# STM32F765BGT6 register map
File version: 1.0
Registers are 32-bit, access not given, reset 0x0 unless marked. A register's access mark holds for its fields unless they carry their own. Offsets are from the block's base; [hi:lo] are bit positions; {n}, {i} and the like mark numbered series.

## MDIOS
Base 0x40017800
0x00 CR
  [12:8] PORT_ADDRESS, [31:4] s, [3] EEI, [2] RDIE, [1] WRIE, [0] EN
0x04 WRFR
  [31:0] WRF
0x08 CWRFR
  [31:0] CWRF
0x0C RDFR
  [31:0] RDF
0x10 CRDFR
  [31:0] CRDF
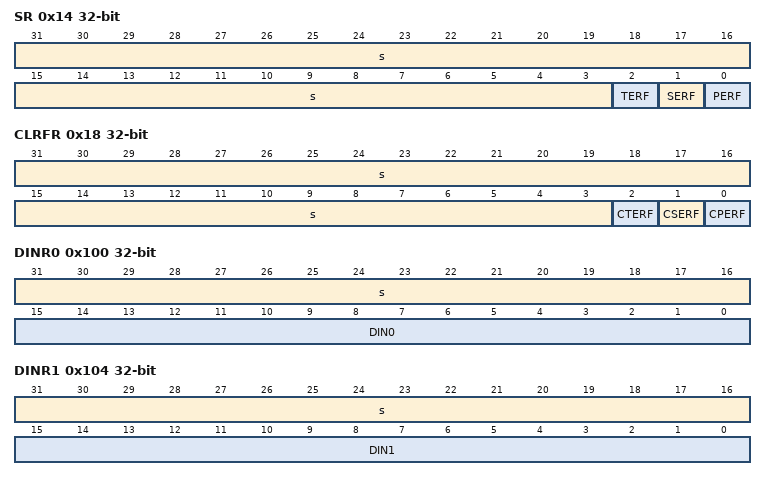
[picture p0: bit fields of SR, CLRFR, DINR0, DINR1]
0x14 SR
  [31:3] s, [2] TERF, [1] SERF, [0] PERF
0x18 CLRFR
  [31:3] s, [2] CTERF, [1] CSERF, [0] CPERF
0x100 DINR0
  [31:16] s, [15:0] DIN0
0x104 DINR1
  [31:16] s, [15:0] DIN1
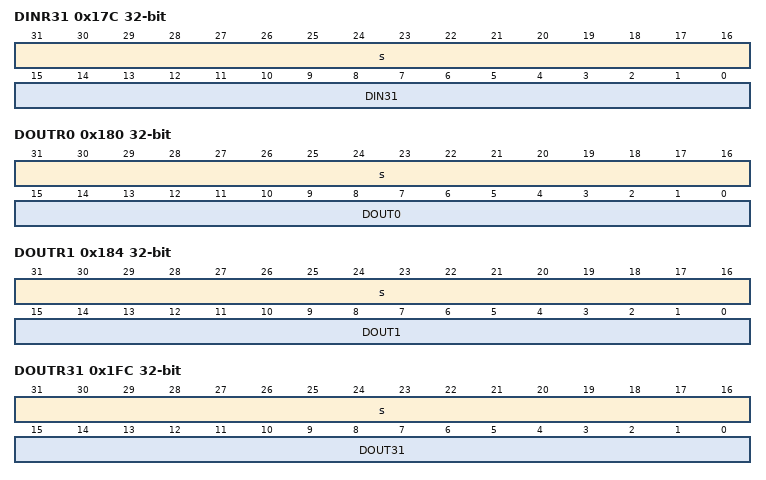
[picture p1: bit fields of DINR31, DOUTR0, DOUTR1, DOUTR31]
0x17C DINR31
  [31:16] s, [15:0] DIN31
0x180 DOUTR0
  [31:16] s, [15:0] DOUT0
0x184 DOUTR1
  [31:16] s, [15:0] DOUT1
0x1FC DOUTR31
  [31:16] s, [15:0] DOUT31

## GPIOA
Base 0x40020000
Same registers: GPIOB 0x40020400
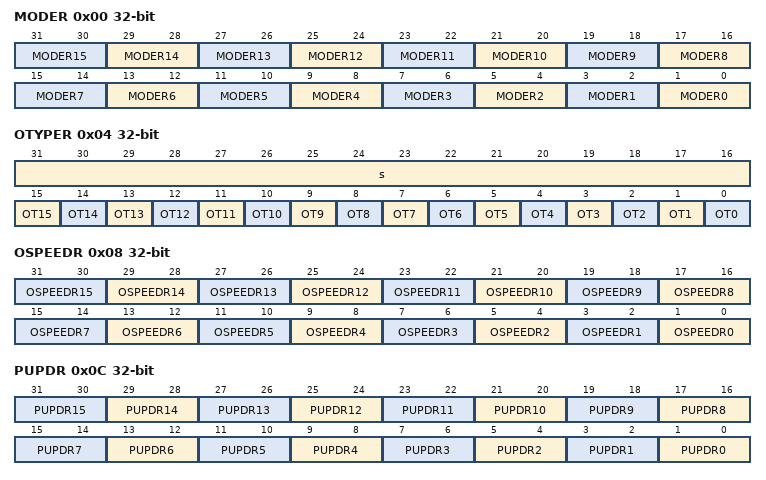
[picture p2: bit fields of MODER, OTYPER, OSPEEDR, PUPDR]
0x00 MODER
  [2n+1:2n] MODER{n} (n=0..15)
0x04 OTYPER
  [31:16] s, [n] OT{n} (n=0..15)
0x08 OSPEEDR
  [2n+1:2n] OSPEEDR{n} (n=0..15)
0x0C PUPDR
  [2n+1:2n] PUPDR{n} (n=0..15)
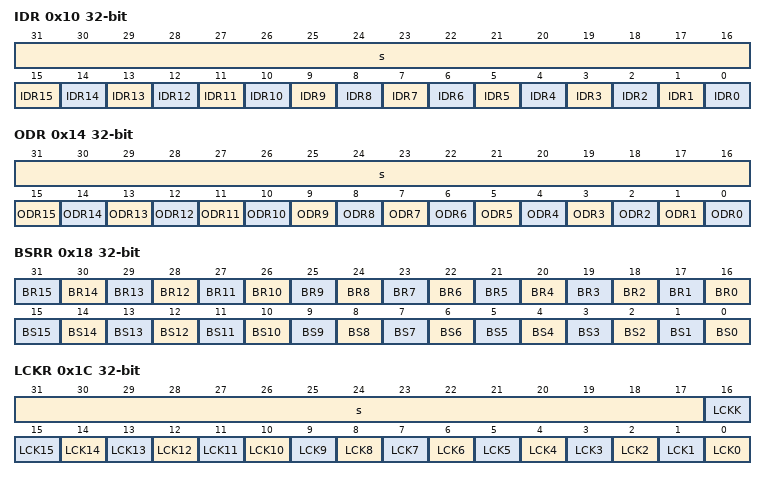
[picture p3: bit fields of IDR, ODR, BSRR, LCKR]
0x10 IDR
  [31:16] s, [n] IDR{n} (n=0..15)
0x14 ODR
  [31:16] s, [n] ODR{n} (n=0..15)
0x18 BSRR
  [n+16] BR{n} (n=0..15), [n] BS{n} (n=0..15)
0x1C LCKR
  [31:17] s, [16] LCKK, [n] LCK{n} (n=0..15)
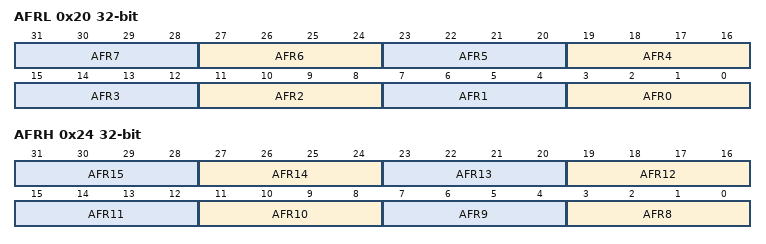
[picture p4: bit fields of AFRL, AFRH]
0x20 AFRL
  [4n+3:4n] AFR{n} (n=0..7)
0x24 AFRH
  [4n-29:4n-32] AFR{n} (n=8..15)

## GPIOC
Base 0x40020800
Registers as GPIOA, without PUPDR.

## GPIOD
Base 0x40020C00
Registers as GPIOA, without PUPDR.

## GPIOE
Base 0x40021000
Registers as GPIOA, without PUPDR.

## GPIOF
Base 0x40021400
Registers as GPIOA, without PUPDR.

## GPIOG
Base 0x40021800
Registers as GPIOA, without PUPDR.

## GPIOH
Base 0x40021C00
Registers as GPIOA, without PUPDR.

## GPIOI
Base 0x40022000
Registers as GPIOA, without PUPDR.

## GPIOJ
Base 0x40022400
Registers as GPIOA, without PUPDR.

## GPIOK
Base 0x40022800
Registers as GPIOA, without PUPDR.

## CRC
Base 0x40023000
0x00 DR
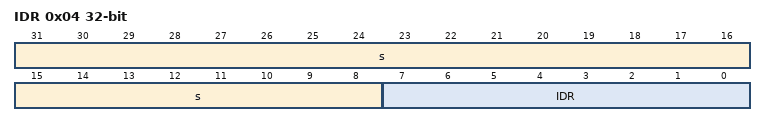
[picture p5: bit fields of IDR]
0x04 IDR
  [31:8] s, [7:0] IDR
0x08 CR
  [7] REV_OUT, [6:5] REV_IN, [4:3] POLYSIZE, [31:1] s, [0] RESET
0x10 INIT
  [31:0] CRC_INIT
0x14 POL
  [31:0] Polynomialcoefficients

## FLASH
Base 0x40023C00
0x00 ACR
  [11] ARTRST, [9] ARTEN, [8] PRFTEN, [31:4] s, [3:0] LATENCY
0x04 KEYR
  [31:0] KEY
0x08 OPTKEYR
0x0C SR
  [16] BSY, [7] ERSERR, [6] PGPERR, [5] PGAERR, [4] WRPERR, [31:2] s, [1] OPERR, [0] EOP
0x10 CR
  [31] LOCK, [25] ERRIE, [24] EOPIE, [16] STRT, [15] MER2, [30:10] s, [9:8] PSIZE, [7:3] SNB, [2] MER/MER1, [1] SER, [0] PG
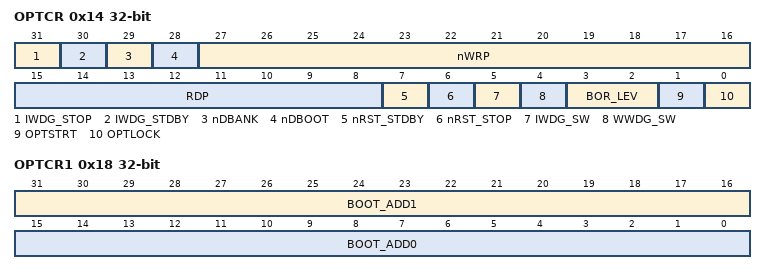
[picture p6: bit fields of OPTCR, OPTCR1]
0x14 OPTCR
  [31] IWDG_STOP, [30] IWDG_STDBY, [29] nDBANK, [28] nDBOOT, [27:16] nWRP, [15:8] RDP, [7] nRST_STDBY, [6] nRST_STOP, [5] IWDG_SW, [4] WWDG_SW, [3:2] BOR_LEV, [1] OPTSTRT, [0] OPTLOCK
0x18 OPTCR1
  [31:16] BOOT_ADD1, [15:0] BOOT_ADD0

## DMA1
Base 0x40026000
Same registers: DMA2 0x40026400
0x00 LISR
  [27] TCIF3, [26] HTIF3, [25] TEIF3, [24] DMEIF3, [22] FEIF3, [21] TCIF2, [20] HTIF2, [19] TEIF2, [18] DMEIF2, [16] FEIF2, [11] TCIF1, [10] HTIF1, [9] TEIF1, [8] DMEIF1, [6] FEIF1, [5] TCIF0, [4] HTIF0, [3] TEIF0, [2] DMEIF0, [31:1] s, [0] FEIF0
0x04 HISR
  [27] TCIF7, [26] HTIF7, [25] TEIF7, [24] DMEIF7, [22] FEIF7, [21] TCIF6, [20] HTIF6, [19] TEIF6, [18] DMEIF6, [16] FEIF6, [11] TCIF5, [10] HTIF5, [9] TEIF5, [8] DMEIF5, [6] FEIF5, [5] TCIF4, [4] HTIF4, [3] TEIF4, [2] DMEIF4, [31:1] s, [0] FEIF4
0x08 LIFCR
  [27] CTCIF3, [26] CHTIF3, [25] TEIF3, [24] CDMEIF3, [22] CFEIF3, [21] CTCIF2, [20] CHTIF2, [19] CTEIF2, [18] CDMEIF2, [16] CFEIF2, [11] CTCIF1, [10] CHTIF1, [9] CTEIF1, [8] CDMEIF1, [6] CFEIF1, [5] CTCIF0, [4] CHTIF0, [3] CTEIF0, [2] CDMEIF0, [31:1] s, [0] CFEIF0
0x0C HIFCR
  [27] CTCIF7, [26] CHTIF7, [25] CTEIF7, [24] CDMEIF7, [22] CFEIF7, [21] CTCIF6, [20] CHTIF6, [19] CTEIF6, [18] CDMEIF6, [16] CFEIF6, [11] CTCIF5, [10] CHTIF5, [9] CTEIF5, [8] CDMEIF5, [6] CFEIF5, [5] CTCIF4, [4] CHTIF4, [3] CTEIF4, [2] CDMEIF4, [31:1] s, [0] CFEIF4
{0x10+0x18*i} S{i}CR (i=0..7)
  [28:25] CHSEL, [24:23] MBURST, [22:21] PBURST, [31:20] s, [19] CT, [18] DBM, [17:16] PL, [15] PINCOS, [14:13] MSIZE, [12:11] PSIZE, [10] MINC, [9] PINC, [8] CIRC, [7:6] DIR, [5] PFCTRL, [4] TCIE, [3] HTIE, [2] TEIE, [1] DMEIE, [0] EN
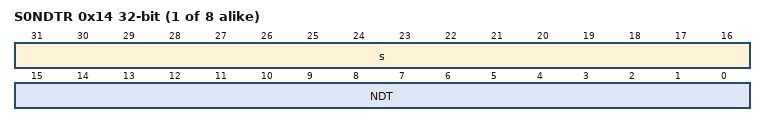
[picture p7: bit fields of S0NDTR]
{0x14+0x18*i} S{i}NDTR (i=0..7)
  [31:16] s, [15:0] NDT
{0x18+0x18*i} S{i}PAR (i=0..7)
  [31:0] PA
{0x1C+0x18*i} S{i}M0AR (i=0..7)
  [31:0] M0A
{0x20+0x18*i} S{i}M1AR (i=0..7)
  [31:0] M1A
{0x24+0x18*i} S{i}FCR (i=0..7)
  [7] FEIE, [31:6] s, [5:3] FS, [2] DMDIS, [1:0] FTH
